# apollo4b register map
Vendor: Ambiq Micro; Series: Apollo; File version: 1.0
CPU: CM4 r1p0, little endian, MPU, FPU, I-cache, D-cache, VTOR, ITCM, DTCM, 3 interrupt priority bits, 0 interrupts
Registers are 32-bit, read-write, reset 0x0 unless marked. A register's access mark holds for its fields unless they carry their own. Offsets are from the block's base; [hi:lo] are bit positions; {n}, {i} and the like mark numbered series; 'fields as' and 'values as' point back to an identical list.

## GPIO (part 1 of 4) — General Purpose IO
Base 0x40010000
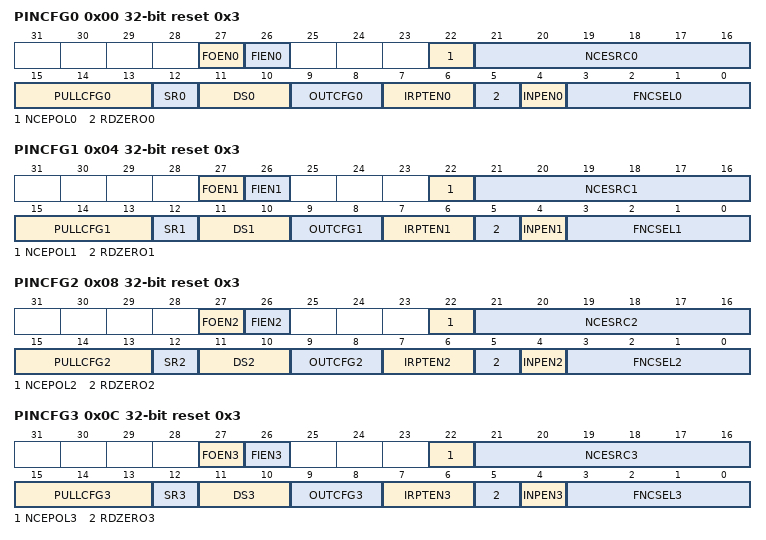
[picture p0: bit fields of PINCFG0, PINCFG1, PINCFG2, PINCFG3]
0x00 PINCFG0 reset 0x3 — Controls the operation of GPIO pin 0.
  [27] FOEN0 — Force output enable active regardless of function selected. Otherwise the selected function will enable the output only when needed
  [26] FIEN0 — Force input enable active regardless of function selected. Otherwise the selected function will enable the input only when needed
  [22] NCEPOL0 — Polarity select for NCE for GPIO 0
    0=LOW (Polarity is active low); 1=HIGH (Polarity is active high)
  [21:16] NCESRC0 — IOMSTR/MSPI N Chip Select 0, DISP control signals DE, CSX, and CS. Polarity is determined by CE_POLARITY field
    {v}=IOM0CE{v} (IOM 0 NCE {v} module) (v=0..3); {v}=IOM1CE{v-4} (IOM 1 NCE {v-4} module) (v=4..7); {v}=IOM2CE{v-8} (IOM 2 NCE {v-8} module) (v=8..11); {v}=IOM3CE{v-12} (IOM 3 NCE {v-12} module) (v=12..15); {v}=IOM4CE{v-16} (IOM 4 NCE {v-16} module) (v=16..19); {v}=IOM5CE{v-20} (IOM 5 NCE {v-20} module) (v=20..23); {v}=IOM6CE{v-24} (IOM 6 NCE {v-24} module) (v=24..27); {v}=IOM7CE{v-28} (IOM 7 NCE {v-28} module) (v=28..31); 32=MSPI0CEN0 (MSPI 0 NCE 0 module); 33=MSPI0CEN1 (MSPI 0 NCE 1 module); 34=MSPI1CEN0 (MSPI 1 NCE 0 module); 35=MSPI1CEN1 (MSPI 1 NCE 1 module); 36=MSPI2CEN0 (MSPI 2 NCE 0 module); 37=MSPI2CEN1 (MSPI 2 NCE 1 module); 38=DC_DPI_DE (DC DPI DE module); 39=DISP_CONT_CSX (DISP CONT CSX module); 40=DC_SPI_CS_N (DC SPI CS_N module); 41=DC_QSPI_CS_N (DC QSPI CS_N module); 42=DC_RESX (DC module RESX)
  [15:13] PULLCFG0 — Pullup/Pulldown configuration for GPIO 0
    0=DIS (No pullup or pulldown selected); 1=PD50K (50K Pulldown selected); 2=PU15K (1.5K Pullup selected); 3=PU6K (6K Pullup selected); 4=PU12K (12K Pullup selected); 5=PU24K (24K Pullup selected); 6=PU50K (50K Pullup selected); 7=PU100K (100K Pullup selected)
  [12] SR0 — Configure the slew rate
  [11:10] DS0 — Drive strength selection for GPIO 0
    0=0P1X (0.1x output driver selected); 1=0P5X (0.5x output driver selected)
  [9:8] OUTCFG0 — Pin IO mode selection for GPIO pin 0
    0=DIS (Output Disabled); 1=PUSHPULL (Output configured in push pull mode. Will drive 0 and 1 values on pin.); 2=OD (Output configured in open drain mode. Will only drive pin low, tristate otherwise.); 3=TS (Output configured in Tristate-able push pull mode. Will drive 0, 1 of HiZ on pin.)
  [7:6] IRPTEN0 — Interrupt enable for GPIO 0
    0=DIS (Interrupts are disabled for this GPIO); 1=INTFALL (Interrupts are enabled for falling edge transition on this GPIO); 2=INTRISE (Interrupts are enabled for rising edge transitions on this GPIO); 3=INTANY (Interrupts are enabled for any edge transition on this GPIO)
  [5] RDZERO0 — Return 0 for read data on GPIO 0
  [4] INPEN0 — Input enable for GPIO 0
  [3:0] FNCSEL0 — Function select for GPIO pin 0
    0=SWTRACECLK (Serial Wire Debug Trace Clock); 1=SLSCL (I2C Slave clock); 2=SLSCK (SPI Slave clock); 3=GPIO (General purpose I/O); 4=UART0TX (UART transmit output (UART 0)); 5=UART1TX (UART transmit output (UART 1)); 6=CT0 (Timer/Counter input or output; Selection of direction is done via CTIMER register settings.); 7=NCE0 (IOMSTR/MSPI N Chip Select. Polarity is determined by CE_POLARITY field); 8=OBSBUS0 (Observation bus bit 0); 9=VCMPO (Output of the voltage comparator signal); 11=FPIO (Fast PIO)
0x04 PINCFG1 reset 0x3 — Controls the operation of GPIO pin 1.
  [27] FOEN1 — Force output enable active regardless of function selected. Otherwise the selected function will enable the output only when needed
  [26] FIEN1 — Force input enable active regardless of function selected. Otherwise the selected function will enable the input only when needed
  [22] NCEPOL1 — Polarity select for NCE for GPIO 1
    values as PINCFG0.NCEPOL0
  [21:16] NCESRC1 — IOMSTR/MSPI N Chip Select 1, DISP control signals DE, CSX, and CS. Polarity is determined by CE_POLARITY field
    values as PINCFG0.NCESRC0
  [15:13] PULLCFG1 — Pullup/Pulldown configuration for GPIO 1
    values as PINCFG0.PULLCFG0
  [12] SR1 — Configure the slew rate
  [11:10] DS1 — Drive strength selection for GPIO 1
    values as PINCFG0.DS0
  [9:8] OUTCFG1 — Pin IO mode selection for GPIO pin 1
    values as PINCFG0.OUTCFG0
  [7:6] IRPTEN1 — Interrupt enable for GPIO 1
    values as PINCFG0.IRPTEN0
  [5] RDZERO1 — Return 0 for read data on GPIO 1
  [4] INPEN1 — Input enable for GPIO 1
  [3:0] FNCSEL1 — Function select for GPIO pin 1
    0=SWTRACE0 (Serial Wire Debug Trace Output 0); 1=SLSDAWIR3 (I2C Slave I/O data (I2C) 3 Wire Data (SPI)); 2=SLMOSI (SPI Slave input data); 3=GPIO (General purpose I/O); 4=UART2TX (UART transmit output (UART 2)); 5=UART3TX (UART transmit output (UART 3)); 6=CT1 (Timer/Counter input or output; Selection of direction is done via CTIMER register settings.); 7=NCE1 (IOMSTR/MSPI N Chip Select. Polarity is determined by CE_POLARITY field); 8=OBSBUS1 (Observation bus bit 1); 9=VCMPO (Output of the voltage comparator signal); 11=FPIO (Fast PIO); 15=SCANIN4 (Internal function (SCAN))
0x08 PINCFG2 reset 0x3 — Controls the operation of GPIO pin 2.
  [27] FOEN2 — Force output enable active regardless of function selected. Otherwise the selected function will enable the output only when needed
  [26] FIEN2 — Force input enable active regardless of function selected. Otherwise the selected function will enable the input only when needed
  [22] NCEPOL2 — Polarity select for NCE for GPIO 2
    values as PINCFG0.NCEPOL0
  [21:16] NCESRC2 — IOMSTR/MSPI N Chip Select 2, DISP control signals DE, CSX, and CS. Polarity is determined by CE_POLARITY field
    values as PINCFG0.NCESRC0
  [15:13] PULLCFG2 — Pullup/Pulldown configuration for GPIO 2
    values as PINCFG0.PULLCFG0
  [12] SR2 — Configure the slew rate
  [11:10] DS2 — Drive strength selection for GPIO 2
    values as PINCFG0.DS0
  [9:8] OUTCFG2 — Pin IO mode selection for GPIO pin 2
    values as PINCFG0.OUTCFG0
  [7:6] IRPTEN2 — Interrupt enable for GPIO 2
    values as PINCFG0.IRPTEN0
  [5] RDZERO2 — Return 0 for read data on GPIO 2
  [4] INPEN2 — Input enable for GPIO 2
  [3:0] FNCSEL2 — Function select for GPIO pin 2
    0=SWTRACE1 (Serial Wire Debug Trace Output 1); 1=SLMISO (SPI Slave output data); 2=TRIG1 (ADC trigger input); 3=GPIO (General purpose I/O); 4=UART0RX (UART receive input (UART 0)); 5=UART1RX (UART receive input (UART 1)); 6=CT2 (Timer/Counter input or output; Selection of direction is done via CTIMER register settings.); 7=NCE2 (IOMSTR/MSPI N Chip Select. Polarity is determined by CE_POLARITY field); 8=OBSBUS2 (Observation bus bit 2); 9=VCMPO (Output of the voltage comparator signal); 11=FPIO (Fast PIO); 15=SCANRSTN (Internal function (SCAN))
0x0C PINCFG3 reset 0x3 — Controls the operation of GPIO pin 3.
  [27] FOEN3 — Force output enable active regardless of function selected. Otherwise the selected function will enable the output only when needed
  [26] FIEN3 — Force input enable active regardless of function selected. Otherwise the selected function will enable the input only when needed
  [22] NCEPOL3 — Polarity select for NCE for GPIO 3
    values as PINCFG0.NCEPOL0
  [21:16] NCESRC3 — IOMSTR/MSPI N Chip Select 3, DISP control signals DE, CSX, and CS. Polarity is determined by CE_POLARITY field
    values as PINCFG0.NCESRC0
  [15:13] PULLCFG3 — Pullup/Pulldown configuration for GPIO 3
    values as PINCFG0.PULLCFG0
  [12] SR3 — Configure the slew rate
  [11:10] DS3 — Drive strength selection for GPIO 3
    values as PINCFG0.DS0
  [9:8] OUTCFG3 — Pin IO mode selection for GPIO pin 3
    values as PINCFG0.OUTCFG0
  [7:6] IRPTEN3 — Interrupt enable for GPIO 3
    values as PINCFG0.IRPTEN0
  [5] RDZERO3 — Return 0 for read data on GPIO 3
  [4] INPEN3 — Input enable for GPIO 3
  [3:0] FNCSEL3 — Function select for GPIO pin 3
    0=SWTRACE2 (Serial Wire Debug Trace Output 2); 1=SLnCE (SPI Slave chip enable); 2=SWO (Serial Wire Output); 3=GPIO (General purpose I/O); 4=UART2RX (UART receive input (UART 2)); 5=UART3RX (UART receive input (UART 3)); 6=CT3 (Timer/Counter input or output; Selection of direction is done via CTIMER register settings.); 7=NCE3 (IOMSTR/MSPI N Chip Select. Polarity is determined by CE_POLARITY field); 8=OBSBUS3 (Observation bus bit 3); 11=FPIO (Fast PIO); 15=SCANIN5 (Internal function (SCAN))
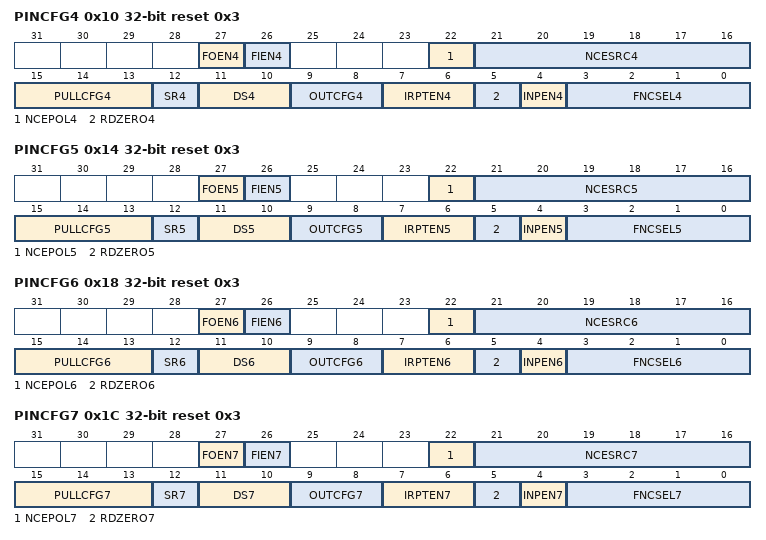
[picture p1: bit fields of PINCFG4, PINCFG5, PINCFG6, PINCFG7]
0x10 PINCFG4 reset 0x3 — Controls the operation of GPIO pin 4.
  [27] FOEN4 — Force output enable active regardless of function selected. Otherwise the selected function will enable the output only when needed
  [26] FIEN4 — Force input enable active regardless of function selected. Otherwise the selected function will enable the input only when needed
  [22] NCEPOL4 — Polarity select for NCE for GPIO 4
    values as PINCFG0.NCEPOL0
  [21:16] NCESRC4 — IOMSTR/MSPI N Chip Select 4, DISP control signals DE, CSX, and CS. Polarity is determined by CE_POLARITY field
    values as PINCFG0.NCESRC0
  [15:13] PULLCFG4 — Pullup/Pulldown configuration for GPIO 4
    values as PINCFG0.PULLCFG0
  [12] SR4 — Configure the slew rate
  [11:10] DS4 — Drive strength selection for GPIO 4
    values as PINCFG0.DS0
  [9:8] OUTCFG4 — Pin IO mode selection for GPIO pin 4
    values as PINCFG0.OUTCFG0
  [7:6] IRPTEN4 — Interrupt enable for GPIO 4
    values as PINCFG0.IRPTEN0
  [5] RDZERO4 — Return 0 for read data on GPIO 4
  [4] INPEN4 — Input enable for GPIO 4
  [3:0] FNCSEL4 — Function select for GPIO pin 4
    0=SWTRACE3 (Serial Wire Debug Trace Output 3); 1=SLINT (Configurable Slave Interrupt); 2=32KHzXT (32kHZ from analog); 3=GPIO (General purpose I/O); 4=UART0RTS (UART Request to Send (RTS) (UART 0)); 5=UART1RTS (UART Request to Send (RTS) (UART 1)); 6=CT4 (Timer/Counter input or output; Selection of direction is done via CTIMER register settings.); 7=NCE4 (IOMSTR/MSPI N Chip Select. Polarity is determined by CE_POLARITY field); 8=OBSBUS4 (Observation bus bit 4); 9=I2S0_SDIN (I2S Data input (I2S Master/Slave 2)); 10=I2S1_SDIN (I2S Data input (I2S Master/Slave 2)); 11=FPIO (Fast PIO); 12=FLB_TDO (Internal function (Flash Bist)); 13=FLLOAD_DIR (Internal function (Flash parallel load)); 14=MDA_TDO (Internal function (MBIST)); 15=OPCG_TRIG (Internal function (SCAN))
0x14 PINCFG5 reset 0x3 — Controls the operation of GPIO pin 5.
  [27] FOEN5 — Force output enable active regardless of function selected. Otherwise the selected function will enable the output only when needed
  [26] FIEN5 — Force input enable active regardless of function selected. Otherwise the selected function will enable the input only when needed
  [22] NCEPOL5 — Polarity select for NCE for GPIO 5
    values as PINCFG0.NCEPOL0
  [21:16] NCESRC5 — IOMSTR/MSPI N Chip Select 5, DISP control signals DE, CSX, and CS. Polarity is determined by CE_POLARITY field
    values as PINCFG0.NCESRC0
  [15:13] PULLCFG5 — Pullup/Pulldown configuration for GPIO 5
    values as PINCFG0.PULLCFG0
  [12] SR5 — Configure the slew rate
  [11:10] DS5 — Drive strength selection for GPIO 5
    0=0P1X (0.1x output driver selected); 1=0P5X (0.5x output driver selected); 2=0P75X (0.75x output driver selected); 3=1P0X (1.0x output driver selected)
  [9:8] OUTCFG5 — Pin IO mode selection for GPIO pin 5
    values as PINCFG0.OUTCFG0
  [7:6] IRPTEN5 — Interrupt enable for GPIO 5
    values as PINCFG0.IRPTEN0
  [5] RDZERO5 — Return 0 for read data on GPIO 5
  [4] INPEN5 — Input enable for GPIO 5
  [3:0] FNCSEL5 — Function select for GPIO pin 5
    0=M0SCL (Serial I2C Master Clock output (IOM 0)); 1=M0SCK (Serial SPI Master Clock output (IOM 0)); 2=I2S0_CLK (Bidirectional I2S Bit clock. Operates in output mode in master mode and input mode for slave mode. (I2S Master/Slave 2)); 3=GPIO (General purpose I/O); 4=UART2RTS (UART Request to Send (RTS) (UART 2)); 5=UART3RTS (UART Request to Send (RTS) (UART 3)); 6=CT5 (Timer/Counter input or output; Selection of direction is done via CTIMER register settings.); 7=NCE5 (IOMSTR/MSPI N Chip Select. Polarity is determined by CE_POLARITY field); 8=OBSBUS5 (Observation bus bit 5); 10=I2S1_CLK (Bidirectional I2S Bit clock. Operates in output mode in master mode and input mode for slave mode. (I2S Master/Slave 2)); 11=FPIO (Fast PIO); 12=FLB_TDI (Internal function (Flash Bist)); 13=FLLOAD_DATA (Internal function (Flash parallel load)); 14=MDA_SRST (Internal function (MBIST)); 15=DFT_ISO (Internal function (SCAN))
0x18 PINCFG6 reset 0x3 — Controls the operation of GPIO pin 6.
  [27] FOEN6 — Force output enable active regardless of function selected. Otherwise the selected function will enable the output only when needed
  [26] FIEN6 — Force input enable active regardless of function selected. Otherwise the selected function will enable the input only when needed
  [22] NCEPOL6 — Polarity select for NCE for GPIO 6
    values as PINCFG0.NCEPOL0
  [21:16] NCESRC6 — IOMSTR/MSPI N Chip Select 6, DISP control signals DE, CSX, and CS. Polarity is determined by CE_POLARITY field
    values as PINCFG0.NCESRC0
  [15:13] PULLCFG6 — Pullup/Pulldown configuration for GPIO 6
    values as PINCFG0.PULLCFG0
  [12] SR6 — Configure the slew rate
  [11:10] DS6 — Drive strength selection for GPIO 6
    values as PINCFG5.DS5
  [9:8] OUTCFG6 — Pin IO mode selection for GPIO pin 6
    values as PINCFG0.OUTCFG0
  [7:6] IRPTEN6 — Interrupt enable for GPIO 6
    values as PINCFG0.IRPTEN0
  [5] RDZERO6 — Return 0 for read data on GPIO 6
  [4] INPEN6 — Input enable for GPIO 6
  [3:0] FNCSEL6 — Function select for GPIO pin 6
    0=M0SDAWIR3 (Serial I2C Master Data I/O (I2C Mode) Serial SPI Master Data I/O (SPI 3 wire mode) (IOM 0)); 1=M0MOSI (Serial SPI Master MOSI output (IOM 0)); 2=I2S0_DATA (Bidirectional I2S Data. Operates in output mode in master mode and input mode for slave mode. (I2S Master/Slave 2)); 3=GPIO (General purpose I/O); 4=UART0CTS (UART Clear to Send (CTS) (UART 0)); 5=UART1CTS (UART Clear to Send (CTS) (UART 1)); 6=CT6 (Timer/Counter input or output; Selection of direction is done via CTIMER register settings.); 7=NCE6 (IOMSTR/MSPI N Chip Select. Polarity is determined by CE_POLARITY field); 8=OBSBUS6 (Observation bus bit 6); 9=I2S0_SDOUT (I2S Data output (I2S Master/Slave 2)); 10=I2S1_SDOUT (I2S Data output (I2S Master/Slave 2)); 11=FPIO (Fast PIO); 15=SCANIN6 (Internal function (SCAN))
0x1C PINCFG7 reset 0x3 — Controls the operation of GPIO pin 7.
  [27] FOEN7 — Force output enable active regardless of function selected. Otherwise the selected function will enable the output only when needed
  [26] FIEN7 — Force input enable active regardless of function selected. Otherwise the selected function will enable the input only when needed
  [22] NCEPOL7 — Polarity select for NCE for GPIO 7
    values as PINCFG0.NCEPOL0
  [21:16] NCESRC7 — IOMSTR/MSPI N Chip Select 7, DISP control signals DE, CSX, and CS. Polarity is determined by CE_POLARITY field
    values as PINCFG0.NCESRC0
  [15:13] PULLCFG7 — Pullup/Pulldown configuration for GPIO 7
    values as PINCFG0.PULLCFG0
  [12] SR7 — Configure the slew rate
  [11:10] DS7 — Drive strength selection for GPIO 7
    values as PINCFG5.DS5
  [9:8] OUTCFG7 — Pin IO mode selection for GPIO pin 7
    values as PINCFG0.OUTCFG0
  [7:6] IRPTEN7 — Interrupt enable for GPIO 7
    values as PINCFG0.IRPTEN0
  [5] RDZERO7 — Return 0 for read data on GPIO 7
  [4] INPEN7 — Input enable for GPIO 7
  [3:0] FNCSEL7 — Function select for GPIO pin 7
    0=M0MISO (Serial SPI MASTER MISO input (IOM 0)); 1=TRIG0 (ADC trigger input); 2=I2S0_WS (Bidirectional I2S L/R clock. Operates in output mode in master mode and input mode for slave mode. (I2S Master/Slave 2)); 3=GPIO (General purpose I/O); 4=UART2CTS (UART Clear to Send (CTS) (UART 2)); 5=UART3CTS (UART Clear to Send (CTS) (UART 3)); 6=CT7 (Timer/Counter input or output; Selection of direction is done via CTIMER register settings.); 7=NCE7 (IOMSTR/MSPI N Chip Select. Polarity is determined by CE_POLARITY field); 8=OBSBUS7 (Observation bus bit 7); 10=I2S1_WS (Bidirectional I2S L/R clock. Operates in output mode in master mode and input mode for slave mode. (I2S Master/Slave 2)); 11=FPIO (Fast PIO); 15=SCANIN7 (Internal function (SCAN))
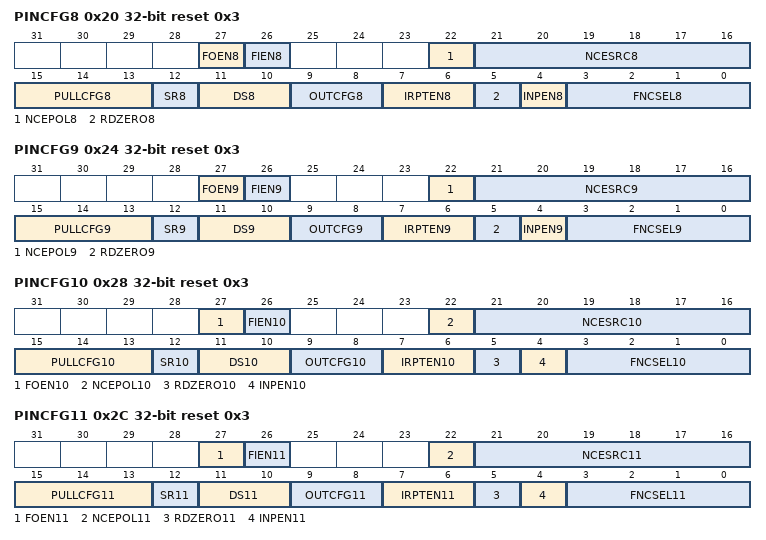
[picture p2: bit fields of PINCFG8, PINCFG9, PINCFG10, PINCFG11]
0x20 PINCFG8 reset 0x3 — Controls the operation of GPIO pin 8.
  [27] FOEN8 — Force output enable active regardless of function selected. Otherwise the selected function will enable the output only when needed
  [26] FIEN8 — Force input enable active regardless of function selected. Otherwise the selected function will enable the input only when needed
  [22] NCEPOL8 — Polarity select for NCE for GPIO 8
    values as PINCFG0.NCEPOL0
  [21:16] NCESRC8 — IOMSTR/MSPI N Chip Select 8, DISP control signals DE, CSX, and CS. Polarity is determined by CE_POLARITY field
    values as PINCFG0.NCESRC0
  [15:13] PULLCFG8 — Pullup/Pulldown configuration for GPIO 8
    values as PINCFG0.PULLCFG0
  [12] SR8 — Configure the slew rate
  [11:10] DS8 — Drive strength selection for GPIO 8
    values as PINCFG5.DS5
  [9:8] OUTCFG8 — Pin IO mode selection for GPIO pin 8
    values as PINCFG0.OUTCFG0
  [7:6] IRPTEN8 — Interrupt enable for GPIO 8
    values as PINCFG0.IRPTEN0
  [5] RDZERO8 — Return 0 for read data on GPIO 8
  [4] INPEN8 — Input enable for GPIO 8
  [3:0] FNCSEL8 — Function select for GPIO pin 8
    0=CMPRF1 (Comparator reference 1); 1=TRIG1 (ADC trigger input); 3=GPIO (General purpose I/O); 4=M1SCL (Serial I2C Master Clock output (IOM 1)); 5=M1SCK (Serial SPI Master Clock output (IOM 1)); 6=CT8 (Timer/Counter input or output; Selection of direction is done via CTIMER register settings.); 7=NCE8 (IOMSTR/MSPI N Chip Select. Polarity is determined by CE_POLARITY field); 8=OBSBUS8 (Observation bus bit 8); 11=FPIO (Fast PIO); 15=SCANOUT4 (Internal function (SCAN))
0x24 PINCFG9 reset 0x3 — Controls the operation of GPIO pin 9.
  [27] FOEN9 — Force output enable active regardless of function selected. Otherwise the selected function will enable the output only when needed
  [26] FIEN9 — Force input enable active regardless of function selected. Otherwise the selected function will enable the input only when needed
  [22] NCEPOL9 — Polarity select for NCE for GPIO 9
    values as PINCFG0.NCEPOL0
  [21:16] NCESRC9 — IOMSTR/MSPI N Chip Select 9, DISP control signals DE, CSX, and CS. Polarity is determined by CE_POLARITY field
    values as PINCFG0.NCESRC0
  [15:13] PULLCFG9 — Pullup/Pulldown configuration for GPIO 9
    values as PINCFG0.PULLCFG0
  [12] SR9 — Configure the slew rate
  [11:10] DS9 — Drive strength selection for GPIO 9
    values as PINCFG5.DS5
  [9:8] OUTCFG9 — Pin IO mode selection for GPIO pin 9
    values as PINCFG0.OUTCFG0
  [7:6] IRPTEN9 — Interrupt enable for GPIO 9
    values as PINCFG0.IRPTEN0
  [5] RDZERO9 — Return 0 for read data on GPIO 9
  [4] INPEN9 — Input enable for GPIO 9
  [3:0] FNCSEL9 — Function select for GPIO pin 9
    0=CMPRF0 (Comparator reference 0); 1=TRIG2 (ADC trigger input); 3=GPIO (General purpose I/O); 4=M1SDAWIR3 (Serial I2C Master Data I/O (I2C Mode) Serial SPI Master Data I/O (SPI 3 wire mode) (IOM 1)); 5=M1MOSI (Serial SPI Master MOSI output (IOM 1)); 6=CT9 (Timer/Counter input or output; Selection of direction is done via CTIMER register settings.); 7=NCE9 (IOMSTR/MSPI N Chip Select. Polarity is determined by CE_POLARITY field); 8=OBSBUS9 (Observation bus bit 9); 11=FPIO (Fast PIO); 15=SCANOUT5 (Internal function (SCAN))
0x28 PINCFG10 reset 0x3 — Controls the operation of GPIO pin 10.
  [27] FOEN10 — Force output enable active regardless of function selected. Otherwise the selected function will enable the output only when needed
  [26] FIEN10 — Force input enable active regardless of function selected. Otherwise the selected function will enable the input only when needed
  [22] NCEPOL10 — Polarity select for NCE for GPIO 10
    values as PINCFG0.NCEPOL0
  [21:16] NCESRC10 — IOMSTR/MSPI N Chip Select 10, DISP control signals DE, CSX, and CS. Polarity is determined by CE_POLARITY field
    values as PINCFG0.NCESRC0
  [15:13] PULLCFG10 — Pullup/Pulldown configuration for GPIO 10
    values as PINCFG0.PULLCFG0
  [12] SR10 — Configure the slew rate
  [11:10] DS10 — Drive strength selection for GPIO 10
    values as PINCFG5.DS5
  [9:8] OUTCFG10 — Pin IO mode selection for GPIO pin 10
    values as PINCFG0.OUTCFG0
  [7:6] IRPTEN10 — Interrupt enable for GPIO 10
    values as PINCFG0.IRPTEN0
  [5] RDZERO10 — Return 0 for read data on GPIO 10
  [4] INPEN10 — Input enable for GPIO 10
  [3:0] FNCSEL10 — Function select for GPIO pin 10
    0=CMPIN0 (Voltage comparator input 0); 1=TRIG3 (ADC trigger input); 3=GPIO (General purpose I/O); 4=M1MISO (Serial SPI MASTER MISO input (IOM 1)); 6=CT10 (Timer/Counter input or output; Selection of direction is done via CTIMER register settings.); 7=NCE10 (IOMSTR/MSPI N Chip Select. Polarity is determined by CE_POLARITY field); 8=OBSBUS10 (Observation bus bit 10); 9=DISP_TE (Display TE input); 11=FPIO (Fast PIO); 15=OPCG_LOAD (Internal function (SCAN))
0x2C PINCFG11 reset 0x3 — Controls the operation of GPIO pin 11.
  [27] FOEN11 — Force output enable active regardless of function selected. Otherwise the selected function will enable the output only when needed
  [26] FIEN11 — Force input enable active regardless of function selected. Otherwise the selected function will enable the input only when needed
  [22] NCEPOL11 — Polarity select for NCE for GPIO 11
    values as PINCFG0.NCEPOL0
  [21:16] NCESRC11 — IOMSTR/MSPI N Chip Select 11, DISP control signals DE, CSX, and CS. Polarity is determined by CE_POLARITY field
    values as PINCFG0.NCESRC0
  [15:13] PULLCFG11 — Pullup/Pulldown configuration for GPIO 11
    values as PINCFG0.PULLCFG0
  [12] SR11 — Configure the slew rate
  [11:10] DS11 — Drive strength selection for GPIO 11
    values as PINCFG0.DS0
  [9:8] OUTCFG11 — Pin IO mode selection for GPIO pin 11
    values as PINCFG0.OUTCFG0
  [7:6] IRPTEN11 — Interrupt enable for GPIO 11
    values as PINCFG0.IRPTEN0
  [5] RDZERO11 — Return 0 for read data on GPIO 11
  [4] INPEN11 — Input enable for GPIO 11
  [3:0] FNCSEL11 — Function select for GPIO pin 11
    0=CMPIN1 (Voltage comparator input 1); 1=TRIG0 (ADC trigger input); 2=I2S0_CLK (Bidirectional I2S Bit clock. Operates in output mode in master mode and input mode for slave mode. (I2S Master/Slave 2)); 3=GPIO (General purpose I/O); 4=UART2RX (UART receive input (UART 2)); 5=UART3RX (UART receive input (UART 3)); 6=CT11 (Timer/Counter input or output; Selection of direction is done via CTIMER register settings.); 7=NCE11 (IOMSTR/MSPI N Chip Select. Polarity is determined by CE_POLARITY field); 8=OBSBUS11 (Observation bus bit 11); 11=FPIO (Fast PIO); 12=FLB_TCLK (Internal function (Flash Bist)); 13=FLLOAD_ADDR (Internal function (Flash parallel load)); 14=MDA_TCK (Internal function (MBIST)); 15=SCANIN0 (Internal function (SCAN))
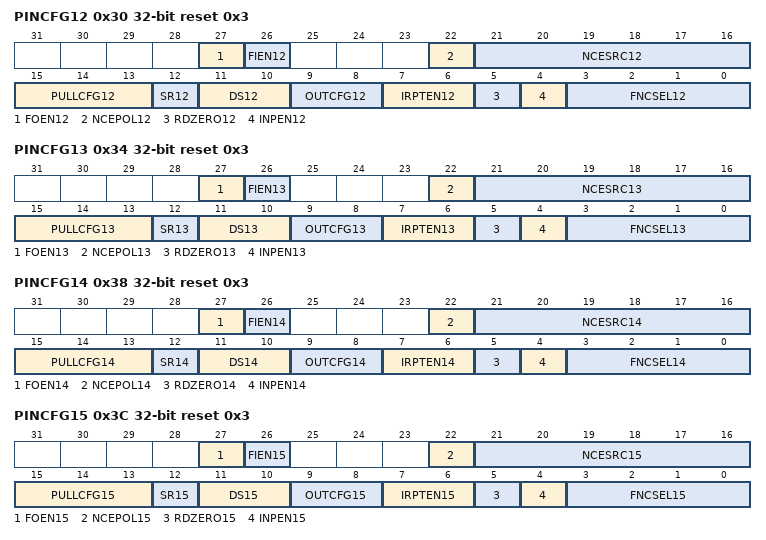
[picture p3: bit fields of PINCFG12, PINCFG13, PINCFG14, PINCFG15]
0x30 PINCFG12 reset 0x3 — Controls the operation of GPIO pin 12.
  [27] FOEN12 — Force output enable active regardless of function selected. Otherwise the selected function will enable the output only when needed
  [26] FIEN12 — Force input enable active regardless of function selected. Otherwise the selected function will enable the input only when needed
  [22] NCEPOL12 — Polarity select for NCE for GPIO 12
    values as PINCFG0.NCEPOL0
  [21:16] NCESRC12 — IOMSTR/MSPI N Chip Select 12, DISP control signals DE, CSX, and CS. Polarity is determined by CE_POLARITY field
    values as PINCFG0.NCESRC0
  [15:13] PULLCFG12 — Pullup/Pulldown configuration for GPIO 12
    values as PINCFG0.PULLCFG0
  [12] SR12 — Configure the slew rate
  [11:10] DS12 — Drive strength selection for GPIO 12
    values as PINCFG0.DS0
  [9:8] OUTCFG12 — Pin IO mode selection for GPIO pin 12
    values as PINCFG0.OUTCFG0
  [7:6] IRPTEN12 — Interrupt enable for GPIO 12
    values as PINCFG0.IRPTEN0
  [5] RDZERO12 — Return 0 for read data on GPIO 12
  [4] INPEN12 — Input enable for GPIO 12
  [3:0] FNCSEL12 — Function select for GPIO pin 12
    0=ADCSE7 (Analog to Digital Converter SE IN7); 1=TRIG1 (ADC trigger input); 2=I2S0_DATA (Bidirectional I2S Data. Operates in output mode in master mode and input mode for slave mode. (I2S Master/Slave 2)); 3=GPIO (General purpose I/O); 4=UART0TX (UART transmit output (UART 0)); 5=UART1TX (UART transmit output (UART 1)); 6=CT12 (Timer/Counter input or output; Selection of direction is done via CTIMER register settings.); 7=NCE12 (IOMSTR/MSPI N Chip Select. Polarity is determined by CE_POLARITY field); 8=OBSBUS12 (Observation bus bit 12); 9=CMPRF2 (Comparator reference 2); 10=I2S0_SDOUT (I2S Data output (I2S Master/Slave 2)); 11=FPIO (Fast PIO); 15=SCANOUT3 (Internal function (SCAN))
0x34 PINCFG13 reset 0x3 — Controls the operation of GPIO pin 13.
  [27] FOEN13 — Force output enable active regardless of function selected. Otherwise the selected function will enable the output only when needed
  [26] FIEN13 — Force input enable active regardless of function selected. Otherwise the selected function will enable the input only when needed
  [22] NCEPOL13 — Polarity select for NCE for GPIO 13
    values as PINCFG0.NCEPOL0
  [21:16] NCESRC13 — IOMSTR/MSPI N Chip Select 13, DISP control signals DE, CSX, and CS. Polarity is determined by CE_POLARITY field
    values as PINCFG0.NCESRC0
  [15:13] PULLCFG13 — Pullup/Pulldown configuration for GPIO 13
    values as PINCFG0.PULLCFG0
  [12] SR13 — Configure the slew rate
  [11:10] DS13 — Drive strength selection for GPIO 13
    values as PINCFG0.DS0
  [9:8] OUTCFG13 — Pin IO mode selection for GPIO pin 13
    values as PINCFG0.OUTCFG0
  [7:6] IRPTEN13 — Interrupt enable for GPIO 13
    values as PINCFG0.IRPTEN0
  [5] RDZERO13 — Return 0 for read data on GPIO 13
  [4] INPEN13 — Input enable for GPIO 13
  [3:0] FNCSEL13 — Function select for GPIO pin 13
    0=ADCSE6 (Analog to Digital Converter SE IN6); 1=TRIG2 (ADC trigger input); 2=I2S0_WS (Bidirectional I2S L/R clock. Operates in output mode in master mode and input mode for slave mode. (I2S Master/Slave 2)); 3=GPIO (General purpose I/O); 4=UART2TX (UART transmit output (UART 2)); 5=UART3TX (UART transmit output (UART 3)); 6=CT13 (Timer/Counter input or output; Selection of direction is done via CTIMER register settings.); 7=NCE13 (IOMSTR/MSPI N Chip Select. Polarity is determined by CE_POLARITY field); 8=OBSBUS13 (Observation bus bit 13); 11=FPIO (Fast PIO); 12=FLB_FCLK (Internal function (Flash Bist)); 13=FLLOAD_DATA (Internal function (Flash parallel load)); 14=MDA_TDI (Internal function (MBIST)); 15=SCANOUT0 (Internal function (SCAN))
0x38 PINCFG14 reset 0x3 — Controls the operation of GPIO pin 14.
  [27] FOEN14 — Force output enable active regardless of function selected. Otherwise the selected function will enable the output only when needed
  [26] FIEN14 — Force input enable active regardless of function selected. Otherwise the selected function will enable the input only when needed
  [22] NCEPOL14 — Polarity select for NCE for GPIO 14
    values as PINCFG0.NCEPOL0
  [21:16] NCESRC14 — IOMSTR/MSPI N Chip Select 14, DISP control signals DE, CSX, and CS. Polarity is determined by CE_POLARITY field
    values as PINCFG0.NCESRC0
  [15:13] PULLCFG14 — Pullup/Pulldown configuration for GPIO 14
    values as PINCFG0.PULLCFG0
  [12] SR14 — Configure the slew rate
  [11:10] DS14 — Drive strength selection for GPIO 14
    values as PINCFG0.DS0
  [9:8] OUTCFG14 — Pin IO mode selection for GPIO pin 14
    values as PINCFG0.OUTCFG0
  [7:6] IRPTEN14 — Interrupt enable for GPIO 14
    values as PINCFG0.IRPTEN0
  [5] RDZERO14 — Return 0 for read data on GPIO 14
  [4] INPEN14 — Input enable for GPIO 14
  [3:0] FNCSEL14 — Function select for GPIO pin 14
    0=ADCSE5 (Analog to Digital Converter SE IN5); 1=TRIG3 (ADC trigger input); 3=GPIO (General purpose I/O); 4=MILLI_CLK (MILLI Clock); 5=UART1RX (UART receive input (UART 1)); 6=CT14 (Timer/Counter input or output; Selection of direction is done via CTIMER register settings.); 7=NCE14 (IOMSTR/MSPI N Chip Select. Polarity is determined by CE_POLARITY field); 8=OBSBUS14 (Observation bus bit 14); 10=I2S0_SDIN (I2S Data input (I2S Master/Slave 2)); 11=FPIO (Fast PIO); 13=FLLOAD_ADDR (Internal function (Flash parallel load)); 14=MDA_TRSTN (Internal function (MBIST)); 15=SCANOUT2 (Internal function (SCAN))
0x3C PINCFG15 reset 0x3 — Controls the operation of GPIO pin 15.
  [27] FOEN15 — Force output enable active regardless of function selected. Otherwise the selected function will enable the output only when needed
  [26] FIEN15 — Force input enable active regardless of function selected. Otherwise the selected function will enable the input only when needed
  [22] NCEPOL15 — Polarity select for NCE for GPIO 15
    values as PINCFG0.NCEPOL0
  [21:16] NCESRC15 — IOMSTR/MSPI N Chip Select 15, DISP control signals DE, CSX, and CS. Polarity is determined by CE_POLARITY field
    values as PINCFG0.NCESRC0
  [15:13] PULLCFG15 — Pullup/Pulldown configuration for GPIO 15
    values as PINCFG0.PULLCFG0
  [12] SR15 — Configure the slew rate
  [11:10] DS15 — Drive strength selection for GPIO 15
    values as PINCFG0.DS0
  [9:8] OUTCFG15 — Pin IO mode selection for GPIO pin 15
    values as PINCFG0.OUTCFG0
  [7:6] IRPTEN15 — Interrupt enable for GPIO 15
    values as PINCFG0.IRPTEN0
  [5] RDZERO15 — Return 0 for read data on GPIO 15
  [4] INPEN15 — Input enable for GPIO 15
  [3:0] FNCSEL15 — Function select for GPIO pin 15
    0=ADCSE4 (Analog to Digital Converter SE IN4); 1=TRIG0 (ADC trigger input); 3=GPIO (General purpose I/O); 4=MILLI_REC_DAT (MILLI Record Data); 5=UART3RX (UART receive input (UART 3)); 6=CT15 (Timer/Counter input or output; Selection of direction is done via CTIMER register settings.); 7=NCE15 (IOMSTR/MSPI N Chip Select. Polarity is determined by CE_POLARITY field); 8=OBSBUS15 (Observation bus bit 15); 10=REFCLK_EXT (External Reference Clock); 11=FPIO (Fast PIO); 13=FLLOAD_DATA (Internal function (Flash parallel load)); 15=SCANOUT1 (Internal function (SCAN))
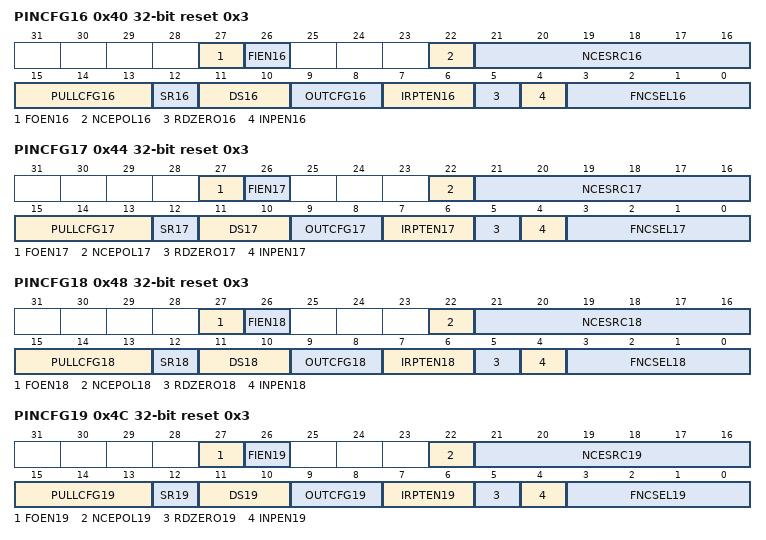
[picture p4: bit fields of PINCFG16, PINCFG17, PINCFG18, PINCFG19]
0x40 PINCFG16 reset 0x3 — Controls the operation of GPIO pin 16.
  [27] FOEN16 — Force output enable active regardless of function selected. Otherwise the selected function will enable the output only when needed
  [26] FIEN16 — Force input enable active regardless of function selected. Otherwise the selected function will enable the input only when needed
  [22] NCEPOL16 — Polarity select for NCE for GPIO 16
    values as PINCFG0.NCEPOL0
  [21:16] NCESRC16 — IOMSTR/MSPI N Chip Select 16, DISP control signals DE, CSX, and CS. Polarity is determined by CE_POLARITY field
    values as PINCFG0.NCESRC0
  [15:13] PULLCFG16 — Pullup/Pulldown configuration for GPIO 16
    values as PINCFG0.PULLCFG0
  [12] SR16 — Configure the slew rate
  [11:10] DS16 — Drive strength selection for GPIO 16
    values as PINCFG0.DS0
  [9:8] OUTCFG16 — Pin IO mode selection for GPIO pin 16
    values as PINCFG0.OUTCFG0
  [7:6] IRPTEN16 — Interrupt enable for GPIO 16
    values as PINCFG0.IRPTEN0
  [5] RDZERO16 — Return 0 for read data on GPIO 16
  [4] INPEN16 — Input enable for GPIO 16
  [3:0] FNCSEL16 — Function select for GPIO pin 16
    0=ADCSE3 (Analog to Digital Converter SE IN3); 1=TRIG1 (ADC trigger input); 2=I2S1_CLK (Bidirectional I2S Bit clock. Operates in output mode in master mode and input mode for slave mode. (I2S Master/Slave 2)); 3=GPIO (General purpose I/O); 4=MILLI_PBDATA1 (MILLI Playback Data1); 5=UART1RTS (UART Request to Send (RTS) (UART 1)); 6=CT16 (Timer/Counter input or output; Selection of direction is done via CTIMER register settings.); 7=NCE16 (IOMSTR/MSPI N Chip Select. Polarity is determined by CE_POLARITY field); 8=OBSBUS0 (Observation bus bit 0); 11=FPIO (Fast PIO); 15=DFT_RET (Internal function (SCAN))
0x44 PINCFG17 reset 0x3 — Controls the operation of GPIO pin 17.
  [27] FOEN17 — Force output enable active regardless of function selected. Otherwise the selected function will enable the output only when needed
  [26] FIEN17 — Force input enable active regardless of function selected. Otherwise the selected function will enable the input only when needed
  [22] NCEPOL17 — Polarity select for NCE for GPIO 17
    values as PINCFG0.NCEPOL0
  [21:16] NCESRC17 — IOMSTR/MSPI N Chip Select 17, DISP control signals DE, CSX, and CS. Polarity is determined by CE_POLARITY field
    values as PINCFG0.NCESRC0
  [15:13] PULLCFG17 — Pullup/Pulldown configuration for GPIO 17
    values as PINCFG0.PULLCFG0
  [12] SR17 — Configure the slew rate
  [11:10] DS17 — Drive strength selection for GPIO 17
    values as PINCFG0.DS0
  [9:8] OUTCFG17 — Pin IO mode selection for GPIO pin 17
    values as PINCFG0.OUTCFG0
  [7:6] IRPTEN17 — Interrupt enable for GPIO 17
    values as PINCFG0.IRPTEN0
  [5] RDZERO17 — Return 0 for read data on GPIO 17
  [4] INPEN17 — Input enable for GPIO 17
  [3:0] FNCSEL17 — Function select for GPIO pin 17
    0=ADCSE2 (Analog to Digital Converter SE IN2); 1=TRIG2 (ADC trigger input); 2=I2S1_DATA (Bidirectional I2S Data. Operates in output mode in master mode and input mode for slave mode. (I2S Master/Slave 2)); 3=GPIO (General purpose I/O); 4=MILLI_PBDATA2 (MILLI Playback Data2); 5=UART3RTS (UART Request to Send (RTS) (UART 3)); 6=CT17 (Timer/Counter input or output; Selection of direction is done via CTIMER register settings.); 7=NCE17 (IOMSTR/MSPI N Chip Select. Polarity is determined by CE_POLARITY field); 8=OBSBUS1 (Observation bus bit 1); 9=I2S1_SDOUT (I2S Data output (I2S Master/Slave 2)); 11=FPIO (Fast PIO); 13=FLLOAD_STRB (Internal function (Flash parallel load)); 14=MDA_TMS (Internal function (MBIST)); 15=OPCG_CLK (Internal function (SCAN))
0x48 PINCFG18 reset 0x3 — Controls the operation of GPIO pin 18.
  [27] FOEN18 — Force output enable active regardless of function selected. Otherwise the selected function will enable the output only when needed
  [26] FIEN18 — Force input enable active regardless of function selected. Otherwise the selected function will enable the input only when needed
  [22] NCEPOL18 — Polarity select for NCE for GPIO 18
    values as PINCFG0.NCEPOL0
  [21:16] NCESRC18 — IOMSTR/MSPI N Chip Select 18, DISP control signals DE, CSX, and CS. Polarity is determined by CE_POLARITY field
    values as PINCFG0.NCESRC0
  [15:13] PULLCFG18 — Pullup/Pulldown configuration for GPIO 18
    values as PINCFG0.PULLCFG0
  [12] SR18 — Configure the slew rate
  [11:10] DS18 — Drive strength selection for GPIO 18
    values as PINCFG0.DS0
  [9:8] OUTCFG18 — Pin IO mode selection for GPIO pin 18
    values as PINCFG0.OUTCFG0
  [7:6] IRPTEN18 — Interrupt enable for GPIO 18
    values as PINCFG0.IRPTEN0
  [5] RDZERO18 — Return 0 for read data on GPIO 18
  [4] INPEN18 — Input enable for GPIO 18
  [3:0] FNCSEL18 — Function select for GPIO pin 18
    0=ADCSE1 (Analog to Digital Converter SE IN1); 1=ANATEST2 (Ambiq Analog test I/O - Unbuffered); 2=I2S1_WS (Bidirectional I2S L/R clock. Operates in output mode in master mode and input mode for slave mode. (I2S Master/Slave 2)); 3=GPIO (General purpose I/O); 4=UART0CTS (UART Clear to Send (CTS) (UART 0)); 5=UART1CTS (UART Clear to Send (CTS) (UART 1)); 6=CT18 (Timer/Counter input or output; Selection of direction is done via CTIMER register settings.); 7=NCE18 (IOMSTR/MSPI N Chip Select. Polarity is determined by CE_POLARITY field); 8=OBSBUS2 (Observation bus bit 2); 11=FPIO (Fast PIO); 12=FLB_TMS (Internal function (Flash Bist)); 13=FLLOAD_DATA (Internal function (Flash parallel load)); 14=MDA_HFRC_EXT (Internal function (MBIST)); 15=SCANIN1 (Internal function (SCAN))
0x4C PINCFG19 reset 0x3 — Controls the operation of GPIO pin 19.
  [27] FOEN19 — Force output enable active regardless of function selected. Otherwise the selected function will enable the output only when needed
  [26] FIEN19 — Force input enable active regardless of function selected. Otherwise the selected function will enable the input only when needed
  [22] NCEPOL19 — Polarity select for NCE for GPIO 19
    values as PINCFG0.NCEPOL0
  [21:16] NCESRC19 — IOMSTR/MSPI N Chip Select 19, DISP control signals DE, CSX, and CS. Polarity is determined by CE_POLARITY field
    values as PINCFG0.NCESRC0
  [15:13] PULLCFG19 — Pullup/Pulldown configuration for GPIO 19
    values as PINCFG0.PULLCFG0
  [12] SR19 — Configure the slew rate
  [11:10] DS19 — Drive strength selection for GPIO 19
    values as PINCFG0.DS0
  [9:8] OUTCFG19 — Pin IO mode selection for GPIO pin 19
    values as PINCFG0.OUTCFG0
  [7:6] IRPTEN19 — Interrupt enable for GPIO 19
    values as PINCFG0.IRPTEN0
  [5] RDZERO19 — Return 0 for read data on GPIO 19
  [4] INPEN19 — Input enable for GPIO 19
  [3:0] FNCSEL19 — Function select for GPIO pin 19
    0=ADCSE0 (Analog to Digital Converter SE IN0); 1=ANATEST1 (Ambiq Analog test I/O - Buffered); 3=GPIO (General purpose I/O); 4=UART2CTS (UART Clear to Send (CTS) (UART 2)); 5=UART3CTS (UART Clear to Send (CTS) (UART 3)); 6=CT19 (Timer/Counter input or output; Selection of direction is done via CTIMER register settings.); 7=NCE19 (IOMSTR/MSPI N Chip Select. Polarity is determined by CE_POLARITY field); 8=OBSBUS3 (Observation bus bit 3); 9=I2S1_SDIN (I2S Data input (I2S Master/Slave 2)); 11=FPIO (Fast PIO); 12=FLB_TRSTN (Internal function (Flash Bist)); 13=FLLOAD_ADDR (Internal function (Flash parallel load)); 15=SCANIN2 (Internal function (SCAN))
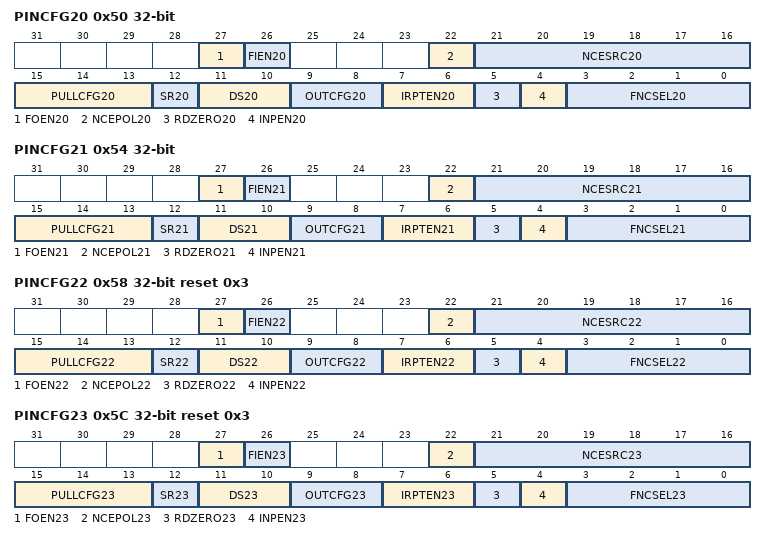
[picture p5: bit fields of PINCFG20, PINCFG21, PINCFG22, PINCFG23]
0x50 PINCFG20 — Controls the operation of GPIO pin 20.
  [27] FOEN20 — Force output enable active regardless of function selected. Otherwise the selected function will enable the output only when needed
  [26] FIEN20 — Force input enable active regardless of function selected. Otherwise the selected function will enable the input only when needed
  [22] NCEPOL20 — Polarity select for NCE for GPIO 20
    values as PINCFG0.NCEPOL0
  [21:16] NCESRC20 — IOMSTR/MSPI N Chip Select 20, DISP control signals DE, CSX, and CS. Polarity is determined by CE_POLARITY field
    values as PINCFG0.NCESRC0
  [15:13] PULLCFG20 — Pullup/Pulldown configuration for GPIO 20
    values as PINCFG0.PULLCFG0
  [12] SR20 — Configure the slew rate
  [11:10] DS20 — Drive strength selection for GPIO 20
    values as PINCFG0.DS0
  [9:8] OUTCFG20 — Pin IO mode selection for GPIO pin 20
    values as PINCFG0.OUTCFG0
  [7:6] IRPTEN20 — Interrupt enable for GPIO 20
    values as PINCFG0.IRPTEN0
  [5] RDZERO20 — Return 0 for read data on GPIO 20
  [4] INPEN20 — Input enable for GPIO 20
  [3:0] FNCSEL20 — Function select for GPIO pin 20
    0=SWDCK (Serial Wire Debug clock input); 1=TRIG1 (ADC trigger input); 3=GPIO (General purpose I/O); 4=UART0TX (UART transmit output (UART 0)); 5=UART1TX (UART transmit output (UART 1)); 6=CT20 (Timer/Counter input or output; Selection of direction is done via CTIMER register settings.); 7=NCE20 (IOMSTR/MSPI N Chip Select. Polarity is determined by CE_POLARITY field); 8=OBSBUS4 (Observation bus bit 4); 11=FPIO (Fast PIO); 15=SCANCLK (Internal function (SCAN))
0x54 PINCFG21 — Controls the operation of GPIO pin 21.
  [27] FOEN21 — Force output enable active regardless of function selected. Otherwise the selected function will enable the output only when needed
  [26] FIEN21 — Force input enable active regardless of function selected. Otherwise the selected function will enable the input only when needed
  [22] NCEPOL21 — Polarity select for NCE for GPIO 21
    values as PINCFG0.NCEPOL0
  [21:16] NCESRC21 — IOMSTR/MSPI N Chip Select 21, DISP control signals DE, CSX, and CS. Polarity is determined by CE_POLARITY field
    values as PINCFG0.NCESRC0
  [15:13] PULLCFG21 — Pullup/Pulldown configuration for GPIO 21
    values as PINCFG0.PULLCFG0
  [12] SR21 — Configure the slew rate
  [11:10] DS21 — Drive strength selection for GPIO 21
    values as PINCFG0.DS0
  [9:8] OUTCFG21 — Pin IO mode selection for GPIO pin 21
    values as PINCFG0.OUTCFG0
  [7:6] IRPTEN21 — Interrupt enable for GPIO 21
    values as PINCFG0.IRPTEN0
  [5] RDZERO21 — Return 0 for read data on GPIO 21
  [4] INPEN21 — Input enable for GPIO 21
  [3:0] FNCSEL21 — Function select for GPIO pin 21
    0=SWDIO (Serial Wire Debug data input/output); 1=TRIG2 (ADC trigger input); 3=GPIO (General purpose I/O); 4=UART2TX (UART transmit output (UART 2)); 5=UART3TX (UART transmit output (UART 3)); 6=CT21 (Timer/Counter input or output; Selection of direction is done via CTIMER register settings.); 7=NCE21 (IOMSTR/MSPI N Chip Select. Polarity is determined by CE_POLARITY field); 8=OBSBUS5 (Observation bus bit 5); 11=FPIO (Fast PIO); 15=SCANSHFT (Internal function (SCAN))
0x58 PINCFG22 reset 0x3 — Controls the operation of GPIO pin 22.
  [27] FOEN22 — Force output enable active regardless of function selected. Otherwise the selected function will enable the output only when needed
  [26] FIEN22 — Force input enable active regardless of function selected. Otherwise the selected function will enable the input only when needed
  [22] NCEPOL22 — Polarity select for NCE for GPIO 22
    values as PINCFG0.NCEPOL0
  [21:16] NCESRC22 — IOMSTR/MSPI N Chip Select 22, DISP control signals DE, CSX, and CS. Polarity is determined by CE_POLARITY field
    values as PINCFG0.NCESRC0
  [15:13] PULLCFG22 — Pullup/Pulldown configuration for GPIO 22
    values as PINCFG0.PULLCFG0
  [12] SR22 — Configure the slew rate
  [11:10] DS22 — Drive strength selection for GPIO 22
    values as PINCFG5.DS5
  [9:8] OUTCFG22 — Pin IO mode selection for GPIO pin 22
    values as PINCFG0.OUTCFG0
  [7:6] IRPTEN22 — Interrupt enable for GPIO 22
    values as PINCFG0.IRPTEN0
  [5] RDZERO22 — Return 0 for read data on GPIO 22
  [4] INPEN22 — Input enable for GPIO 22
  [3:0] FNCSEL22 — Function select for GPIO pin 22
    0=M7SCL (Serial I2C Master Clock output (IOM 7)); 1=M7SCK (Serial SPI Master Clock output (IOM 7)); 2=SWO (Serial Wire Output); 3=GPIO (General purpose I/O); 4=UART0RX (UART receive input (UART 0)); 5=UART1RX (UART receive input (UART 1)); 6=CT22 (Timer/Counter input or output; Selection of direction is done via CTIMER register settings.); 7=NCE22 (IOMSTR/MSPI N Chip Select. Polarity is determined by CE_POLARITY field); 8=OBSBUS6 (Observation bus bit 6); 9=VCMPO (Output of the voltage comparator signal); 11=FPIO (Fast PIO); 15=SCANIN3 (Internal function (SCAN))
0x5C PINCFG23 reset 0x3 — Controls the operation of GPIO pin 23.
  [27] FOEN23 — Force output enable active regardless of function selected. Otherwise the selected function will enable the output only when needed
  [26] FIEN23 — Force input enable active regardless of function selected. Otherwise the selected function will enable the input only when needed
  [22] NCEPOL23 — Polarity select for NCE for GPIO 23
    values as PINCFG0.NCEPOL0
  [21:16] NCESRC23 — IOMSTR/MSPI N Chip Select 23, DISP control signals DE, CSX, and CS. Polarity is determined by CE_POLARITY field
    values as PINCFG0.NCESRC0
  [15:13] PULLCFG23 — Pullup/Pulldown configuration for GPIO 23
    values as PINCFG0.PULLCFG0
  [12] SR23 — Configure the slew rate
  [11:10] DS23 — Drive strength selection for GPIO 23
    values as PINCFG5.DS5
  [9:8] OUTCFG23 — Pin IO mode selection for GPIO pin 23
    values as PINCFG0.OUTCFG0
  [7:6] IRPTEN23 — Interrupt enable for GPIO 23
    values as PINCFG0.IRPTEN0
  [5] RDZERO23 — Return 0 for read data on GPIO 23
  [4] INPEN23 — Input enable for GPIO 23
  [3:0] FNCSEL23 — Function select for GPIO pin 23
    0=M7SDAWIR3 (Serial I2C Master Data I/O (I2C Mode) Serial SPI Master Data I/O (SPI 3 wire mode) (IOM 7)); 1=M7MOSI (Serial SPI Master MOSI output (IOM 7)); 2=SWO (Serial Wire Output); 3=GPIO (General purpose I/O); 4=UART2RX (UART receive input (UART 2)); 5=UART3RX (UART receive input (UART 3)); 6=CT23 (Timer/Counter input or output; Selection of direction is done via CTIMER register settings.); 7=NCE23 (IOMSTR/MSPI N Chip Select. Polarity is determined by CE_POLARITY field); 8=OBSBUS7 (Observation bus bit 7); 9=VCMPO (Output of the voltage comparator signal); 11=FPIO (Fast PIO); 15=SCANOUT6 (Internal function (SCAN))
